# CCFG register map
Vendor: Texas Instruments
Peripheral module from a debugger description file (folder CC26x4).
Registers are 32-bit, read-only, reset 0xFFFFFFFF unless marked. A register's access mark holds for its fields unless they carry their own. Offsets are as the file gives them; lines under a group give offsets from that group; [hi:lo] are bit positions; {n}, {i} and the like mark numbered series; 'fields as' and 'values as' point back to an identical list; <NAME> marks a mode.

## CCFG — Customer configuration area (CCFG)
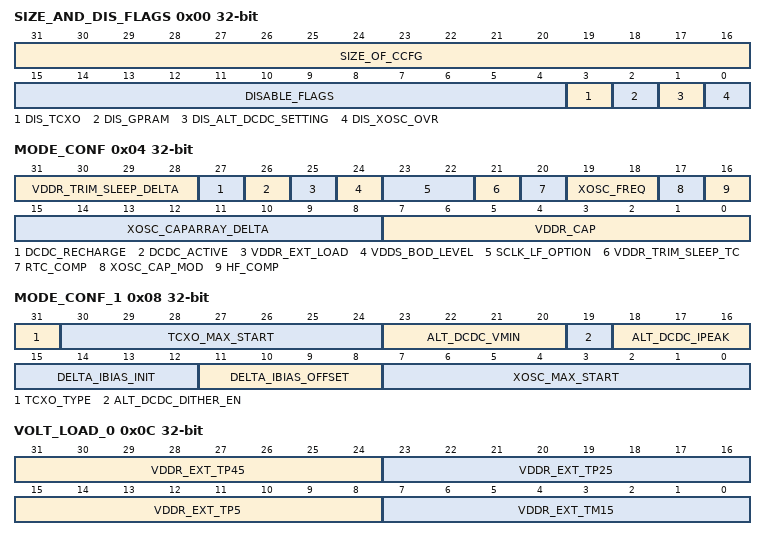
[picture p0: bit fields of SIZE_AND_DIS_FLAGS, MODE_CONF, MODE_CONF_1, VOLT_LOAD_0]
0x00 SIZE_AND_DIS_FLAGS — CCFG Size and Disable Flags
  [31:16] SIZE_OF_CCFG — Total size of CCFG in bytes.
  [15:4] DISABLE_FLAGS — Reserved for future use. Software should not rely on the value of a reserved. Writing any other value than the reset/default value may result in undefined behavior.
  [3] DIS_TCXO — Deprecated. Must be set to 1.
  [2] DIS_GPRAM — Disable GPRAM (or use the 8K VIMS RAM as CACHE RAM). 0: GPRAM is enabled and hence CACHE disabled. 1: GPRAM is disabled and instead CACHE is enabled (default). Notes: - Disabling CACHE will reduce CPU execution speed (up to 60%). - GPRAM is 8 K-bytes in size and located at 0x11000000-0x11001FFF if enabled. See: VIMS:CTL.MODE
  [1] DIS_ALT_DCDC_SETTING — Disable alternate DC/DC settings. 0: Enable alternate DC/DC settings. 1: Disable alternate DC/DC settings. See: MODE_CONF_1.ALT_DCDC_VMIN MODE_CONF_1.ALT_DCDC_DITHER_EN MODE_CONF_1.ALT_DCDC_IPEAK NOTE! The DriverLib function SysCtrl_DCDC_VoltageConditionalControl() must be called regularly to apply this field.
  [0] DIS_XOSC_OVR — Disable XOSC override functionality. 0: Enable XOSC override functionality. 1: Disable XOSC override functionality. See: MODE_CONF_1.DELTA_IBIAS_INIT MODE_CONF_1.DELTA_IBIAS_OFFSET MODE_CONF_1.XOSC_MAX_START
0x04 MODE_CONF — Mode Configuration 0
  [31:28] VDDR_TRIM_SLEEP_DELTA — Signed delta value to apply to the VDDR_TRIM_SLEEP target, minus one. See FCFG1:VOLT_TRIM.VDDR_TRIM_SLEEP_H. 0x8 (-8) : Delta = -7 ... 0xF (-1) : Delta = 0 0x0 (0) : Delta = +1 ... 0x7 (7) : Delta = +8
  [27] DCDC_RECHARGE — DC/DC during recharge in powerdown. 0: Use the DC/DC during recharge in powerdown. 1: Do not use the DC/DC during recharge in powerdown (default). NOTE! The DriverLib function SysCtrl_DCDC_VoltageConditionalControl() must be called regularly to apply this field.
  [26] DCDC_ACTIVE — DC/DC in active mode. 0: Use the DC/DC during active mode. 1: Do not use the DC/DC during active mode (default). NOTE! The DriverLib function SysCtrl_DCDC_VoltageConditionalControl() must be called regularly to apply this field.
  [25] VDDR_EXT_LOAD — For TI internal use only.
  [24] VDDS_BOD_LEVEL — VDDS BOD level. 0: VDDS BOD level is 2.0V (necessary for external load mode, or for maximum PA output power on CC13x4x10). 1: VDDS BOD level is 1.8V (or 1.65V for external regulator mode) (default).
  [23:22] SCLK_LF_OPTION — Select source for SCLK_LF.
    3=RCOSC_LF (Low frequency RCOSC (default)); 2=XOSC_LF (32.768 kHz low frequency XOSC); 1=EXTERNAL_LF (External low frequency clock on DIO defined by EXT_LF_CLK.DIO. The RTC tick speed AON_RTC:SUBSECINC is updated to EXT_LF_CLK.RTC_INCREMENT (done in the SetupTrimDevice() driverlib boot function). External clock must always be running when the chip is in standby for VDDR recharge timing.); 0=XOSC_HF_DLF (31.25 kHz clock derived from 48 MHz XOSC or HPOSC. The RTC tick speed AON_RTC:SUBSECINC is updated to 0x8637BD, corresponding to a 31.25 kHz clock (done in the SetupTrimDevice() driverlib boot function). The device must be blocked from entering Standby mode when using this clock source.)
  [21] VDDR_TRIM_SLEEP_TC — 0x1: VDDR_TRIM_SLEEP_DELTA is not temperature compensated 0x0: TI's Power Manager temperature compensates VDDR_TRIM_SLEEP_DELTA every time Standby mode is entered. When temperature compensation is performed, the delta is calculated this way: Delta = max (delta, min(8, floor(62-temp)/8)) Here, delta is given by VDDR_TRIM_SLEEP_DELTA, and temp is the current temperature in degrees C.
  [20] RTC_COMP — Reserved for future use. Software should not rely on the value of a reserved. Writing any other value than the reset/default value may result in undefined behavior.
  [19:18] XOSC_FREQ — Selects which high frequency oscillator is used (required for radio usage).
    3=24 MHz XOSC_HF. Not supported.; 2=48 MHz XOSC_HF; 1=HPOSC (Internal high precision oscillator.); 0=TCXO (External 48 MHz TCXO. Refer to MODE_CONF_1.TCXO_MAX_START and MODE_CONF_1.TCXO_TYPE bit fields for additional configuration of TCXO.)
  [17] XOSC_CAP_MOD — Enable modification (delta) to XOSC cap-array. Value specified in XOSC_CAPARRAY_DELTA. 0: Apply cap-array delta 1: Do not apply cap-array delta (default)
  [16] HF_COMP — Reserved for future use. Software should not rely on the value of a reserved. Writing any other value than the reset/default value may result in undefined behavior.
  [15:8] XOSC_CAPARRAY_DELTA — Signed 8-bit value, directly modifying trimmed XOSC cap-array step value. Enabled by XOSC_CAP_MOD.
  [7:0] VDDR_CAP — Unsigned 8-bit integer, representing the minimum decoupling capacitance (worst case) on VDDR, in units of 100nF. This should take into account capacitor tolerance and voltage dependent capacitance variation. This bit affects the recharge period calculation when going into powerdown or standby. NOTE! If using the following functions this field must be configured (used by TI RTOS): SysCtrlSetRechargeBeforePowerDown() SysCtrlAdjustRechargeAfterPowerDown()
0x08 MODE_CONF_1 — Mode Configuration 1
  [31] TCXO_TYPE — Selects the TCXO type. 0: CMOS type. Internal common-mode bias will not be enabled. 1: Clipped-sine type. Internal common-mode bias will be enabled when TCXO is used. Bit field value is only valid if MODE_CONF.XOSC_FREQ=0.
  [30:24] TCXO_MAX_START — Maximum TCXO startup time in units of 100us. Bit field value is only valid if MODE_CONF.XOSC_FREQ=0.
  [23:20] ALT_DCDC_VMIN — Minimum voltage for when DC/DC should be used if alternate DC/DC setting is enabled (SIZE_AND_DIS_FLAGS.DIS_ALT_DCDC_SETTING=0). Voltage = (28 + ALT_DCDC_VMIN) / 16. 0: 1.75V 1: 1.8125V ... 14: 2.625V 15: 2.6875V NOTE! The DriverLib function SysCtrl_DCDC_VoltageConditionalControl() must be called regularly to apply this field (handled automatically if using TI RTOS!).
  [19] ALT_DCDC_DITHER_EN — Enable DC/DC dithering if alternate DC/DC setting is enabled (SIZE_AND_DIS_FLAGS.DIS_ALT_DCDC_SETTING=0). 0: Dither disable 1: Dither enable
  [18:16] ALT_DCDC_IPEAK — Inductor peak current if alternate DC/DC setting is enabled (SIZE_AND_DIS_FLAGS.DIS_ALT_DCDC_SETTING=0). Assuming 10uH external inductor! 0: Min 46mA ... 4: Typical 70mA ... 7: Max 87mA
  [15:12] DELTA_IBIAS_INIT — Signed delta value for IBIAS_INIT. Delta value only applies if SIZE_AND_DIS_FLAGS.DIS_XOSC_OVR=0. See FCFG1:AMPCOMP_CTRL1.IBIAS_INIT
  [11:8] DELTA_IBIAS_OFFSET — Signed delta value for IBIAS_OFFSET. Delta value only applies if SIZE_AND_DIS_FLAGS.DIS_XOSC_OVR=0. See FCFG1:AMPCOMP_CTRL1.IBIAS_OFFSET
  [7:0] XOSC_MAX_START — Unsigned value of maximum XOSC startup time (worst case) in units of 100us. Value only applies if SIZE_AND_DIS_FLAGS.DIS_XOSC_OVR=0.
0x0C VOLT_LOAD_0 — Voltage Load 0 Enabled by MODE_CONF.VDDR_EXT_LOAD.
  [31:24] VDDR_EXT_TP45 — Reserved for future use. Software should not rely on the value of a reserved. Writing any other value than the reset/default value may result in undefined behavior.
  [23:16] VDDR_EXT_TP25 — Reserved for future use. Software should not rely on the value of a reserved. Writing any other value than the reset/default value may result in undefined behavior.
  [15:8] VDDR_EXT_TP5 — Reserved for future use. Software should not rely on the value of a reserved. Writing any other value than the reset/default value may result in undefined behavior.
  [7:0] VDDR_EXT_TM15 — Reserved for future use. Software should not rely on the value of a reserved. Writing any other value than the reset/default value may result in undefined behavior.
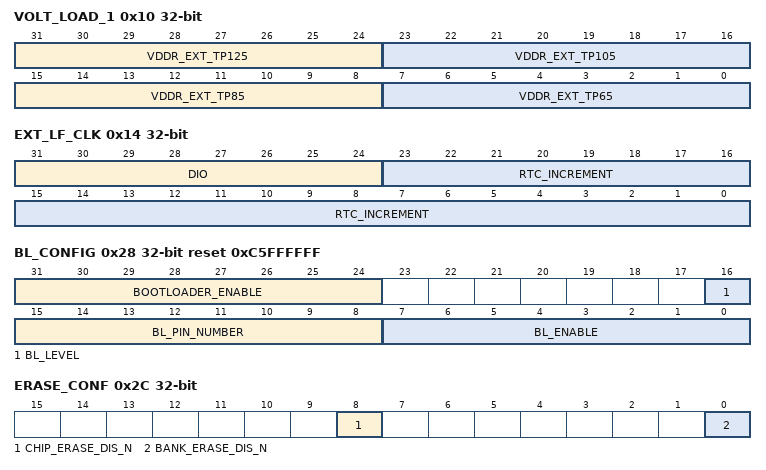
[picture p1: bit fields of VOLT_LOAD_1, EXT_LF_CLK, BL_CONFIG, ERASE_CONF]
0x10 VOLT_LOAD_1 — Voltage Load 1 Enabled by MODE_CONF.VDDR_EXT_LOAD.
  [31:24] VDDR_EXT_TP125 — Reserved for future use. Software should not rely on the value of a reserved. Writing any other value than the reset/default value may result in undefined behavior.
  [23:16] VDDR_EXT_TP105 — Reserved for future use. Software should not rely on the value of a reserved. Writing any other value than the reset/default value may result in undefined behavior.
  [15:8] VDDR_EXT_TP85 — Reserved for future use. Software should not rely on the value of a reserved. Writing any other value than the reset/default value may result in undefined behavior.
  [7:0] VDDR_EXT_TP65 — Reserved for future use. Software should not rely on the value of a reserved. Writing any other value than the reset/default value may result in undefined behavior.
0x14 EXT_LF_CLK — Extern LF clock configuration
  [31:24] DIO — Unsigned integer, selecting the DIO to supply external 32 kHz clock as SCLK_LF when MODE_CONF.SCLK_LF_OPTION is set to EXTERNAL.
  [23:0] RTC_INCREMENT — Unsigned integer, defining the input frequency of the external clock and is written to AON_RTC:SUBSECINC.VALUEINC. Defined as follows: EXT_LF_CLK.RTC_INCREMENT = 2^38/InputClockFrequency in Hertz (e.g.: RTC_INCREMENT=0x800000 for InputClockFrequency=32768 Hz)
0x18 IEEE_MAC_0 — IEEE MAC Address 0
  [31:0] ADDR — Bits[31:0] of the 64-bits custom IEEE MAC address. If different from 0xFFFFFFFF then the value of this field is applied otherwise use value from FCFG:MAC_15_4_0.
0x1C IEEE_MAC_1 — IEEE MAC Address 1
  [31:0] ADDR — Bits[63:32] of the 64-bits custom IEEE MAC address. If different from 0xFFFFFFFF then the value of this field is applied, otherwise use value from FCFG:MAC_15_4_1.
0x20 IEEE_BLE_0 — IEEE BLE Address 0
  [31:0] ADDR — Bits[31:0] of the 64-bits custom IEEE BLE address. If different from 0xFFFFFFFF then the value of this field is applied otherwise use value from FCFG:MAC_BLE_0.
0x24 IEEE_BLE_1 — IEEE BLE Address 1
  [31:0] ADDR — Bits[63:32] of the 64-bits custom IEEE BLE address. If different from 0xFFFFFFFF then the value of this field is applied, otherwise use value from FCFG:MAC_BLE_1.
0x28 BL_CONFIG reset 0xC5FFFFFF — Bootloader Configuration Configures the functionality of the ROM boot loader. If both the boot loader is enabled by the BOOTLOADER_ENABLE field and the boot loader backdoor is enabled by the BL_ENABLE field it is possible to force entry of the ROM boot loader even if a valid image is present in flash.
  [31:24] BOOTLOADER_ENABLE — Bootloader enable. Boot loader can be accessed if IMAGE_VALID_CONF.IMAGE_VALID is an invalid vector table address or BL_ENABLE is enabled (and conditions for boot loader backdoor are met). 0xC5: Boot loader is enabled. Any other value: Boot loader is disabled.
  [16] BL_LEVEL — Sets the active level of the selected DIO number BL_PIN_NUMBER if boot loader backdoor is enabled by the BL_ENABLE field. 0: Active low. 1: Active high.
  [15:8] BL_PIN_NUMBER — DIO number that is level checked if the boot loader backdoor is enabled by the BL_ENABLE field.
  [7:0] BL_ENABLE — Enables the boot loader backdoor. 0xC5: Boot loader backdoor is enabled. Any other value: Boot loader backdoor is disabled. NOTE! Boot loader must be enabled (see BOOTLOADER_ENABLE) if boot loader backdoor is enabled.
0x2C ERASE_CONF — Erase Configuration
  [8] CHIP_ERASE_DIS_N — Chip erase. This bit controls if a chip erase requested through the JTAG WUC TAP will be ignored in a following boot caused by a reset of the MCU VD. A successful chip erase operation will force the content of the flash main bank back to the state as it was when delivered by TI. 0: Disable. Any chip erase request detected during boot will be ignored. 1: Enable. Any chip erase request detected during boot will be performed by the boot FW.
  [0] BANK_ERASE_DIS_N — Bank erase. This bit controls if the ROM serial boot loader will accept a received Bank Erase command (COMMAND_BANK_ERASE). A successful Bank Erase operation will erase all main bank sectors not protected by write protect configuration bits in CCFG. 0: Disable the boot loader bank erase function. 1: Enable the boot loader bank erase function.
0x30 ERASE_CONF_1 — Erase Configuration 1
  [0] WEPROT_CCFG_N — WriteErase protect the CCFG sector Setting this bit = 0 will set FLASH:WEPROT_AUX_BY1.WEPROT_B0_CCFG_BY1 = 1 during boot and hence WriteErase protect the CCFG
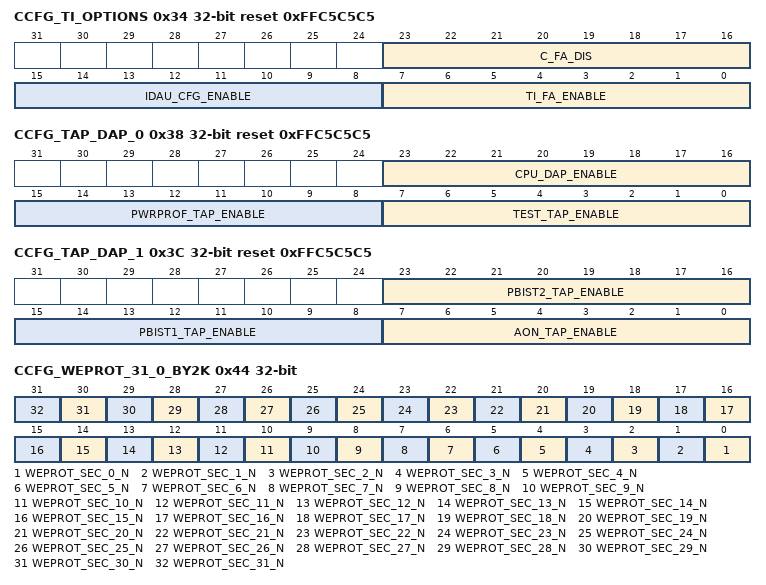
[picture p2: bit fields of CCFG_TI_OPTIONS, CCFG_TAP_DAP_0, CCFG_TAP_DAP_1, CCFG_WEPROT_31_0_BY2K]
0x34 CCFG_TI_OPTIONS reset 0xFFC5C5C5 — TI Options
  [23:16] C_FA_DIS — Option to disable failure analysis without customer password. If C_FA_DIS != 0xC5, CKEY (CKEY0.KEY, CKEY1.KEY, CKEY2.KEY, CKEY2.KEY) must be provided to TI for failure analysis to be possible. 0xC5: Failure analysis without customer password is enabled All other values: Failure analysis without customer password is disabled
  [15:8] IDAU_CFG_ENABLE — IDAU configuration. 0xC5: Disable IDAU configuration controlled by TRUSTZONE_FLASH_CFG and TRUSTZONE_SRAM_CFG. All other values: Enable IDAU configuration controlled by TRUSTZONE_FLASH_CFG and TRUSTZONE_SRAM_CFG.
  [7:0] TI_FA_ENABLE — TI Failure Analysis. 0xC5: Enable the functionality of unlocking the TI FA (TI Failure Analysis) option with the unlock code. All other values: Disable the functionality of unlocking the TI FA option with the unlock code.
0x38 CCFG_TAP_DAP_0 reset 0xFFC5C5C5 — Test Access Points Enable 0
  [23:16] CPU_DAP_ENABLE — Enable CPU DAP. 0xC5: Main CPU DAP access is enabled during power-up/system-reset by ROM boot FW. Any other value: Main CPU DAP access will remain disabled out of power-up/system-reset.
  [15:8] PWRPROF_TAP_ENABLE — Enable PWRPROF TAP. 0xC5: PWRPROF TAP access is enabled during power-up/system-reset by ROM boot FW if enabled by corresponding configuration value in FCFG1 defined by TI. Any other value: PWRPROF TAP access will remain disabled out of power-up/system-reset.
  [7:0] TEST_TAP_ENABLE — Enable Test TAP. 0xC5: TEST TAP access is enabled during power-up/system-reset by ROM boot FW if enabled by corresponding configuration value in FCFG1 defined by TI. Any other value: TEST TAP access will remain disabled out of power-up/system-reset.
0x3C CCFG_TAP_DAP_1 reset 0xFFC5C5C5 — Test Access Points Enable 1
  [23:16] PBIST2_TAP_ENABLE — Enable PBIST2 TAP. 0xC5: PBIST2 TAP access is enabled during power-up/system-reset by ROM boot FW if enabled by corresponding configuration value in FCFG1 defined by TI. Any other value: PBIST2 TAP access will remain disabled out of power-up/system-reset.
  [15:8] PBIST1_TAP_ENABLE — Enable PBIST1 TAP. 0xC5: PBIST1 TAP access is enabled during power-up/system-reset by ROM boot FW if enabled by corresponding configuration value in FCFG1 defined by TI. Any other value: PBIST1 TAP access will remain disabled out of power-up/system-reset.
  [7:0] AON_TAP_ENABLE — Enable AON TAP 0xC5: AON TAP access is enabled during power-up/system-reset by ROM boot FW if enabled by corresponding configuration value in FCFG1 defined by TI. Any other value: AON TAP access will remain disabled out of power-up/system-reset.
0x40 IMAGE_VALID_CONF — Image Valid
  [31:0] IMAGE_VALID — This field must have the address value of the start of the flash vector table in order to enable the boot FW in ROM to transfer control to a flash image. Any illegal vector table start address value will force the boot FW in ROM to transfer control to the serial boot loader in ROM.
0x44 CCFG_WEPROT_31_0_BY2K — Protect Sectors 0-31 Each bit write protects one 2KB flash sector from being both programmed and erased. Bit must be set to 0 in order to enable sector WriteErase protect.
  [n] WEPROT_SEC_{n}_N (n=0..31) — 0: Sector protected
{0x44+4i} CCFG_WEPROT_SPARE_{i} (i=1..3) — Spare register for WriteErase configuration
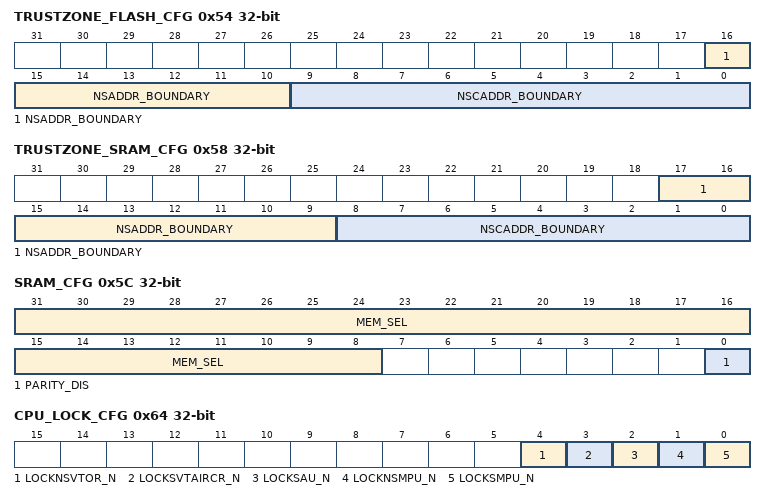
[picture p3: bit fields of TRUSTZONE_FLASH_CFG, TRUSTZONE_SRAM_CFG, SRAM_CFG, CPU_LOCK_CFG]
0x54 TRUSTZONE_FLASH_CFG — Trustzone configuration register for flash
  [16:10] NSADDR_BOUNDARY — Value will be written to PRCM:NVMNSADDR.BOUNDARY by ROM boot FW only if CCFG_TI_OPTIONS.IDAU_CFG_ENABLE != 0xC5.
  [9:0] NSCADDR_BOUNDARY — Value will be written to PRCM:NVMNSCADDR.BOUNDARY by ROM boot FW only if CCFG_TI_OPTIONS.IDAU_CFG_ENABLE != 0xC5.
0x58 TRUSTZONE_SRAM_CFG — Trustzone configuration register for MCU SRAM
  [17:9] NSADDR_BOUNDARY — Value will be written to PRCM:SRAMNSADDR.BOUNDARY by ROM boot FW only if CCFG_TI_OPTIONS.IDAU_CFG_ENABLE != 0xC5.
  [8:0] NSCADDR_BOUNDARY — Value will be written to PRCM:SRAMNSCADDR.BOUNDARY by ROM boot FW only if CCFG_TI_OPTIONS.IDAU_CFG_ENABLE != 0xC5.
0x5C SRAM_CFG — Configuration register for MCU SRAM
  [31:8] MEM_SEL — Value will be written to SRAM_MMR:MEM_CTL.MEM_SEL by ROM boot FW
  [0] PARITY_DIS — Value will be inverted and then written to PRCM:MCUSRAMCFG.PARITY_EN by ROM boot FW
0x64 CPU_LOCK_CFG — Configuration register for MCU CPU lock options
  [4] LOCKNSVTOR_N — Value will be inverted and written to PRCM:CPULOCK.LOCKNSVTOR by ROM boot FW
  [3] LOCKSVTAIRCR_N — Value will be inverted and written to PRCM:CPULOCK.LOCKSVTAIRCR by ROM boot FW
  [2] LOCKSAU_N — Value will be inverted and written to PRCM:CPULOCK.LOCKSAU by ROM boot FW
  [1] LOCKNSMPU_N — Value will be inverted and written to PRCM:CPULOCK.LOCKNSMPU by ROM boot FW
  [0] LOCKSMPU_N — Value will be inverted and written to PRCM:CPULOCK.LOCKSMPU by ROM boot FW
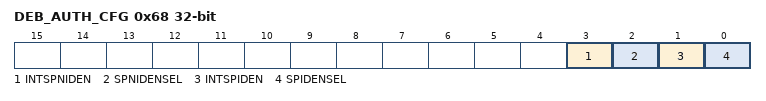
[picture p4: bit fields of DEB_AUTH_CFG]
0x68 DEB_AUTH_CFG — Configuration register for debug authentication
  [3] INTSPNIDEN — Value will be written to CPU_DCB:DAUTHCTRL.INTSPNIDEN by ROM boot FW
  [2] SPNIDENSEL — Value will be written to CPU_DCB:DAUTHCTRL.SPNIDENSEL by ROM boot FW
  [1] INTSPIDEN — Value will be written to CPU_DCB:DAUTHCTRL.INTSPIDEN by ROM boot FW
  [0] SPIDENSEL — Value will be written to CPU_DCB:DAUTHCTRL.SPIDENSEL by ROM boot FW
{0x6C+4i} CKEY{i} reset 0xFFFFFFF (i=0..3) — Customer key
  [31:0] KEY — Bit[{32i+31}:{32i}] of customer key used for XOR of TI unlock code when CCFG_TI_OPTIONS.C_FA_DIS != 0xC5.
